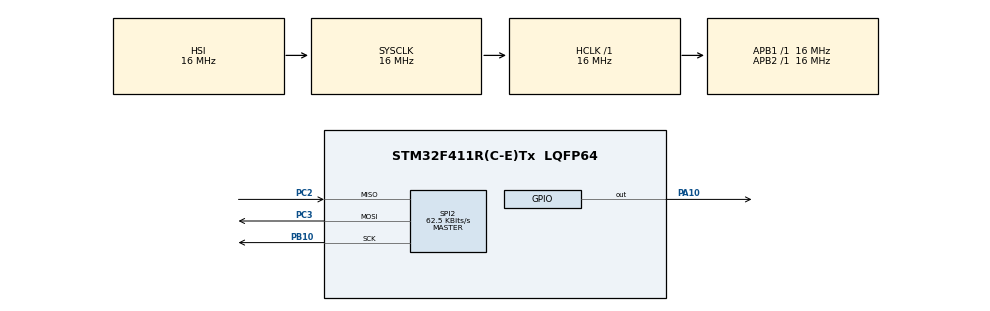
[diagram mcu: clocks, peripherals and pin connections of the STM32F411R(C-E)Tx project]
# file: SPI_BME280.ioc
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Mcu.Family=STM32F4
Mcu.Name=STM32F411R(C-E)Tx
Mcu.Package=LQFP64
NVIC.PriorityGroup=NVIC_PRIORITYGROUP_4
PA10.Signal=GPIO_Output
PB10.Mode=Full_Duplex_Master
PB10.Signal=SPI2_SCK
PC2.Mode=Full_Duplex_Master
PC2.Signal=SPI2_MISO
PC3.Mode=Full_Duplex_Master
PC3.Signal=SPI2_MOSI
ProjectManager.HeapSize=0x200
ProjectManager.StackSize=0x400
ProjectManager.TargetToolchain=STM32CubeIDE
RCC.AHBFreq_Value=16000000
RCC.APB1Freq_Value=16000000
RCC.APB2Freq_Value=16000000
RCC.CortexFreq_Value=16000000
RCC.HSE_VALUE=25000000
RCC.HSI_VALUE=16000000
RCC.LSE_VALUE=32768
RCC.SYSCLKFreq_VALUE=16000000
RCC.VCOOutputFreq_Value=192000000
SPI2.BaudRatePrescaler=SPI_BAUDRATEPRESCALER_256
SPI2.CalculateBaudRate=62.5 KBits/s
SPI2.Direction=SPI_DIRECTION_2LINES
SPI2.Mode=SPI_MODE_MASTER
SPI2.VirtualType=VM_MASTER
board=custom

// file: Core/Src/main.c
/* USER CODE BEGIN Header */
/**
  ******************************************************************************
  * @file           : main.c
  * @brief          : Main program body
  ******************************************************************************
  * @attention
  *
  * Copyright (c) 2022 STMicroelectronics.
  * All rights reserved.
  *
  * This software is licensed under terms that can be found in the LICENSE file
  * in the root directory of this software component.
  * If no LICENSE file comes with this software, it is provided AS-IS.
  *
  ******************************************************************************
  */
/* USER CODE END Header */
#include "main.h"

SPI_HandleTypeDef hspi2;

void SystemClock_Config(void);
static void MX_GPIO_Init(void);
static void MX_SPI2_Init(void);

/* USER CODE BEGIN 0 */
uint8_t tx_buff[6];
uint8_t rx_buff[6];
/* USER CODE END 0 */

int main(void)
{

  /* MCU Configuration--------------------------------------------------------*/

  /* Reset of all peripherals, Initializes the Flash interface and the Systick. */
  HAL_Init();

  /* Configure the system clock */
  SystemClock_Config();

  /* Initialize all configured peripherals */
  MX_GPIO_Init();
  MX_SPI2_Init();

  /* Infinite loop */
  while (1)
  {
	  HAL_SPI_Transmit(&hspi2, 0x76, 1, 10);
	  HAL_Delay(500);
	  HAL_SPI_Receive(&hspi2, rx_buff, 1, 10);
	  HAL_Delay(500);
  }
}

void SystemClock_Config(void)
{
  RCC_OscInitTypeDef RCC_OscInitStruct = {0};
  RCC_ClkInitTypeDef RCC_ClkInitStruct = {0};

  /** Configure the main internal regulator output voltage
  */
  __HAL_RCC_PWR_CLK_ENABLE();
  __HAL_PWR_VOLTAGESCALING_CONFIG(PWR_REGULATOR_VOLTAGE_SCALE1);

  /** Initializes the RCC Oscillators according to the specified parameters
  * in the RCC_OscInitTypeDef structure.
  */
  RCC_OscInitStruct.OscillatorType = RCC_OSCILLATORTYPE_HSI;
  RCC_OscInitStruct.HSIState = RCC_HSI_ON;
  RCC_OscInitStruct.HSICalibrationValue = RCC_HSICALIBRATION_DEFAULT;
  RCC_OscInitStruct.PLL.PLLState = RCC_PLL_NONE;
  if (HAL_RCC_OscConfig(&RCC_OscInitStruct) != HAL_OK)
  {
    Error_Handler();
  }

  /** Initializes the CPU, AHB and APB buses clocks
  */
  RCC_ClkInitStruct.ClockType = RCC_CLOCKTYPE_HCLK|RCC_CLOCKTYPE_SYSCLK
                              |RCC_CLOCKTYPE_PCLK1|RCC_CLOCKTYPE_PCLK2;
  RCC_ClkInitStruct.SYSCLKSource = RCC_SYSCLKSOURCE_HSI;
  RCC_ClkInitStruct.AHBCLKDivider = RCC_SYSCLK_DIV1;
  RCC_ClkInitStruct.APB1CLKDivider = RCC_HCLK_DIV1;
  RCC_ClkInitStruct.APB2CLKDivider = RCC_HCLK_DIV1;

  if (HAL_RCC_ClockConfig(&RCC_ClkInitStruct, FLASH_LATENCY_0) != HAL_OK)
  {
    Error_Handler();
  }
}

static void MX_SPI2_Init(void)
{

  /* SPI2 parameter configuration*/
  hspi2.Instance = SPI2;
  hspi2.Init.Mode = SPI_MODE_MASTER;
  hspi2.Init.Direction = SPI_DIRECTION_2LINES;
  hspi2.Init.DataSize = SPI_DATASIZE_8BIT;
  hspi2.Init.CLKPolarity = SPI_POLARITY_LOW;
  hspi2.Init.CLKPhase = SPI_PHASE_1EDGE;
  hspi2.Init.NSS = SPI_NSS_SOFT;
  hspi2.Init.BaudRatePrescaler = SPI_BAUDRATEPRESCALER_256;
  hspi2.Init.FirstBit = SPI_FIRSTBIT_MSB;
  hspi2.Init.TIMode = SPI_TIMODE_DISABLE;
  hspi2.Init.CRCCalculation = SPI_CRCCALCULATION_DISABLE;
  hspi2.Init.CRCPolynomial = 10;
  if (HAL_SPI_Init(&hspi2) != HAL_OK)
  {
    Error_Handler();
  }

}

static void MX_GPIO_Init(void)
{
  GPIO_InitTypeDef GPIO_InitStruct = {0};

  /* GPIO Ports Clock Enable */
  __HAL_RCC_GPIOC_CLK_ENABLE();
  __HAL_RCC_GPIOB_CLK_ENABLE();
  __HAL_RCC_GPIOA_CLK_ENABLE();

  /*Configure GPIO pin Output Level */
  HAL_GPIO_WritePin(GPIOA, GPIO_PIN_10, GPIO_PIN_RESET);

  /*Configure GPIO pin : PA10 */
  GPIO_InitStruct.Pin = GPIO_PIN_10;
  GPIO_InitStruct.Mode = GPIO_MODE_OUTPUT_PP;
  GPIO_InitStruct.Pull = GPIO_NOPULL;
  GPIO_InitStruct.Speed = GPIO_SPEED_FREQ_LOW;
  HAL_GPIO_Init(GPIOA, &GPIO_InitStruct);

}

void Error_Handler(void)
{
  __disable_irq();
  while (1)
  {
  }
}
